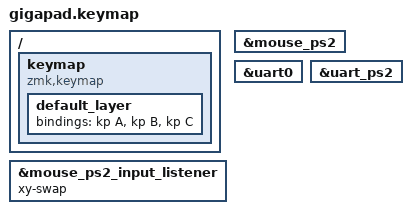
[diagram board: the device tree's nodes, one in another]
#include <behaviors.dtsi>
#include <dt-bindings/zmk/keys.h>
#include <dt-bindings/zmk/bt.h>
#include <dt-bindings/zmk/outputs.h>
#include <dt-bindings/zmk/mouse.h>
#include <dt-bindings/zmk/mouse_settings.h>
#include <behaviors/mouse_keys.dtsi>
#include <behaviors/mouse_setting.dtsi>

  // Only apply these settings on the side that has the TP connected
  // (usually the right side)

   /*
    * Input Listener Config
    */

    &mouse_ps2_input_listener {

      // Adjust pointing device axes.
      // This adjusts the values inside the zmk driver. Some
      // trackpoints also allow you to adjust it in their firmware. Check
      // the driver options below for more info.
         xy-swap;
      // x-invert;
      // y-invert;

      // Set the layer that should automatically activate when the mouse is
      // moving.
      //layer-toggle = <MOUSE_TP>;

      // How long the mouse needs to move for before the layer is activated (to
      // avoid accidental activations while typing) (Default: 250)
      //layer-toggle-delay-ms = <250>;

      // How long to wait, after the last mouse movement, before deactivating
      // the layer (Default: 250)
      //layer-toggle-timeout-ms = <250>;
    };


   /*
    * Mouse Driver Settings
    */

    &mouse_ps2 {

      // How sensitive the TP is (Default: 128)
      // tp-sensitivity = <128>;


      // The maximum mouse movement speed the TP will accelarate to
      // (Default: 97)
      // tp-val6-upper-speed = <97>;


      // Negative Inertia (Default: 6)
      // Makes the TP feel more responsive and "overshoot" less.
      // tp-neg-inertia = <6>;


      // Enable clicking by tapping on the TP.
      // Not all TPs support this.
      // tp-press-to-select;
      // tp-press-to-select-threshold = <10>;


      // Adjust axis settings on the TP
      // Works only on some trackpoints, but may be properly considered by the
      // trackpoint's acceleration features (which may or may not have an
      // impact).
      //
      // Alternatively consider achieving the same effect using the
      //  `input-listener` settings below.
      // tp-xy-swap;
      // tp-x-invert;
      // tp-y-invert;


      // Set sampling rate
      //
      // The frequency at which the mouse samples and sends data (in hz).
      // The default rate is 100. You can try lowering it if you experience
      // connection errors.
      //
      // Higher values than 100 are no improvement in my experience, but will
      // increase battery life and potentially errors in transmissions.
      //
      // These values are allowed: 10,20,40,60,80,100,200
      // sampling-rate = <60>;


      // Disables clicking.
      // Useful when using the PS2 GPIO driver that is prone to
      // erros in transmissions to reduce accidental clicks.
      // disable-clicking;


      // Enable scroll wheel
      // For mouse devices supporting the Intellimouse extension. Not relevant
      // for trackpoints
      // scroll-mode;

    };

    // Enable PS/2 Mouse Devices
    // In `your_keyboard_right.overlay` all devices have `status = "disabled"`.
    // So,they are never compiled into the firmware.
    //
    // Here we enable them, but we do it within the #ifdef HAS_MOUSE_TP code
    // block, which prevents compilation and potential build errors when we
    // undefine HAS_MOUSE_TP in corne_tp.keymap
    &mouse_ps2  {
      status = "okay";
    };

    &mouse_ps2_input_listener {
      status = "okay";
    };



      &uart0 {
        status = "okay";
      };

      &uart_ps2 {
        status="okay";
      };

/ {
    keymap {
        compatible = "zmk,keymap";

        default_layer {
            bindings = <
                // Blackpill onboard user key button
                &kp A

                // Switches connected directly to gpio pins
                &kp B
                &kp C
            >;
        };
    };
};
